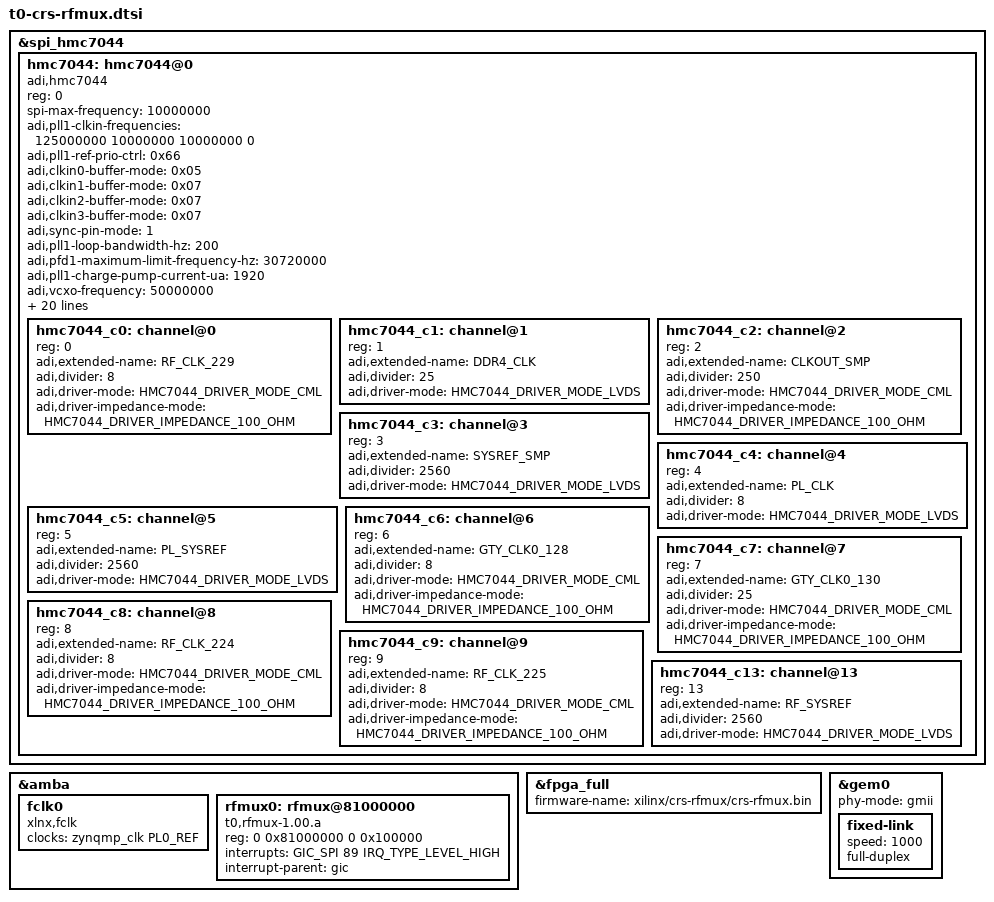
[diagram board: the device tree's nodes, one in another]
/dts-v1/;
/plugin/;

#include <dt-bindings/clock/xlnx-zynqmp-clk.h>
#include <dt-bindings/iio/frequency/hmc7044.h>
#include <dt-bindings/interrupt-controller/arm-gic.h>
#include <dt-bindings/interrupt-controller/irq.h>

&spi_hmc7044 {
	#address-cells = <1>;
	#size-cells = <0>;

	hmc7044: hmc7044@0 {
		#address-cells = <1>;
		#size-cells = <0>;
		#clock-cells = <1>;
		compatible = "adi,hmc7044";
		reg = <0>;
		spi-max-frequency = <10000000>;

		adi,pll1-clkin-frequencies = <125000000 10000000 10000000 0>;

		/* The PLL seems unable to reliably lock to the Ethernet
		* receiver clock, for $reasons we haven't had time to
		* investigate. This tends to cause poor performance. (We don't
		* control the quality of the Ethernet clock anyways, and should
		* be highly suspicious of its fine-scale performance.)
		* Removing all but the SMA and BP options until we've really
		* justified the other settings. */
		adi,pll1-ref-prio-ctrl = <0x66>; /* SMA -> BP -> SMA -> BP */

		/*adi,pll1-ref-prio-ctrl = <0x36>;*/ /* SMA -> BP -> PL -> Ethernet */

		adi,clkin0-buffer-mode  = <0x05>; /* AC */
		adi,clkin1-buffer-mode  = <0x07>; // 100Ω, AC
		adi,clkin2-buffer-mode  = <0x07>; // 100Ω, AC
		adi,clkin3-buffer-mode  = <0x07>; // 100Ω, AC
		adi,sync-pin-mode = <1>;

		adi,pll1-loop-bandwidth-hz = <200>;
		adi,pfd1-maximum-limit-frequency-hz = <30720000>;
		adi,pll1-charge-pump-current-ua = <1920>;

		adi,vcxo-frequency = <50000000>;

		adi,pll2-output-frequency = <2500000000>; /* 2.5 GHz */

		adi,sysref-timer-divider = <2560>; /* 976.5625 kHz */
		adi,pulse-generator-mode = <7>;

		adi,oscin-buffer-mode = <0x15>;

		adi,gpi-controls = <0x00 0x00 0x00 0x11>;
		adi,gpo-controls = <0x1f 0x2b 0x00 0x00>;

		adi,high-performance-mode-clock-dist-enable;

		clock-output-names =
			"hmc7044_out0_RF_CLK_229",
			"hmc7044_out1_DDR4_CLK",
			"hmc7044_out2_CLKOUT_SMP",
			"hmc7044_out3_SYSREF_SMP",
			"hmc7044_out4_PL_CLK",
			"hmc7044_out5_PL_SYSREF",
			"hmc7044_out6_GTY_CLK0_128",
			"hmc7044_out7_GTY_CLK0_130",
			"hmc7044_out8_RF_CLK_224",
			"hmc7044_out9_RF_CLK_225",
			"hmc7044_out10_RF_CLK_226",
			"hmc7044_out11_RF_CLK_227",
			"hmc7044_out12_RF_CLK_228",
			"hmc7044_out13_RF_SYSREF";

		hmc7044_c0: channel@0 {
			reg = <0>;
			adi,extended-name = "RF_CLK_229";
			adi,divider = <8>; /* 312.5 MHz */
			adi,driver-mode = <HMC7044_DRIVER_MODE_CML>;
			adi,driver-impedance-mode = <HMC7044_DRIVER_IMPEDANCE_100_OHM>;
		};
		hmc7044_c1: channel@1 {
			reg = <1>;
			adi,extended-name = "DDR4_CLK";
			adi,divider = <25>; /* 100 MHz */
			adi,driver-mode = <HMC7044_DRIVER_MODE_LVDS>;
		};
		hmc7044_c2: channel@2 {
			reg = <2>;
			adi,extended-name = "CLKOUT_SMP";
			adi,divider = <250>; /* 10 MHz */
			adi,driver-mode = <HMC7044_DRIVER_MODE_CML>;
			adi,driver-impedance-mode = <HMC7044_DRIVER_IMPEDANCE_100_OHM>;
		};
		hmc7044_c3: channel@3 {
			reg = <3>;
			adi,extended-name = "SYSREF_SMP";
			adi,divider = <2560>; /* 976.5625 kHz */
			adi,driver-mode = <HMC7044_DRIVER_MODE_LVDS>;
		};
		hmc7044_c4: channel@4 {
			reg = <4>;
			adi,extended-name = "PL_CLK";
			adi,divider = <8>; /* 312.5 MHz */
			adi,driver-mode = <HMC7044_DRIVER_MODE_LVDS>;
		};
		hmc7044_c5: channel@5 {
			reg = <5>;
			adi,extended-name = "PL_SYSREF";
			adi,divider = <2560>; /* 976.5625 kHz */
			adi,driver-mode = <HMC7044_DRIVER_MODE_LVDS>;
		};
		hmc7044_c6: channel@6 {
			reg = <6>;
			adi,extended-name = "GTY_CLK0_128";
			adi,divider = <8>; /* 312.5 MHz */
			adi,driver-mode = <HMC7044_DRIVER_MODE_CML>;
			adi,driver-impedance-mode = <HMC7044_DRIVER_IMPEDANCE_100_OHM>;
		};
		hmc7044_c7: channel@7 {
			reg = <7>;
			adi,extended-name = "GTY_CLK0_130";
			adi,divider = <25>; /* 100 MHz */
			adi,driver-mode = <HMC7044_DRIVER_MODE_CML>;
			adi,driver-impedance-mode = <HMC7044_DRIVER_IMPEDANCE_100_OHM>;
		};
		hmc7044_c8: channel@8 {
			reg = <8>;
			adi,extended-name = "RF_CLK_224";
			adi,divider = <8>; /* 312.5 MHz */
			adi,driver-mode = <HMC7044_DRIVER_MODE_CML>;
			adi,driver-impedance-mode = <HMC7044_DRIVER_IMPEDANCE_100_OHM>;
		};
		hmc7044_c9: channel@9 {
			reg = <9>;
			adi,extended-name = "RF_CLK_225";
			adi,divider = <8>; /* 312.5 MHz */
			adi,driver-mode = <HMC7044_DRIVER_MODE_CML>;
			adi,driver-impedance-mode = <HMC7044_DRIVER_IMPEDANCE_100_OHM>;
		};
#if 0
		hmc7044_c10: channel@10 {
			reg = <10>;
			adi,extended-name = "RF_CLK_226";
			adi,divider = <8>; /* 312.5 MHz */
			adi,driver-mode = <HMC7044_DRIVER_MODE_CML>;
			adi,driver-impedance-mode = <HMC7044_DRIVER_IMPEDANCE_100_OHM>;
		};
		hmc7044_c11: channel@11 {
			reg = <11>;
			adi,extended-name = "RF_CLK_227";
			adi,divider = <8>; /* 312.5 MHz */
			adi,driver-mode = <HMC7044_DRIVER_MODE_CML>;
			adi,driver-impedance-mode = <HMC7044_DRIVER_IMPEDANCE_100_OHM>;
		};
		hmc7044_c12: channel@12 {
			reg = <12>;
			adi,extended-name = "RF_CLK_228";
			adi,divider = <8>; /* 312.5 MHz */
			adi,driver-mode = <HMC7044_DRIVER_MODE_CML>;
			adi,driver-impedance-mode = <HMC7044_DRIVER_IMPEDANCE_100_OHM>;
		};
#endif
		hmc7044_c13: channel@13 {
			reg = <13>;
			adi,extended-name = "RF_SYSREF";
			adi,divider = <2560>; /* 976.5625 kHz */
			adi,driver-mode = <HMC7044_DRIVER_MODE_LVDS>;
		};
	};
};

&amba {
	/* The rfmux node overrides the SDT-generated axi_slave with a custom
	 * compatible string for the mod_rfmux kernel driver. Other PL nodes
	 * (RFDC, clocks, AFI, DDR4) are provided by the SDT via pl.dtsi.
	 *
	 * The fclk node enables pl_clk0.  The SDT/lopper flow deletes
	 * xlnx,fclk nodes from the Linux DT, so we must provide one here.
	 * Without it the PS-PL clock gate stays off and all AXI transactions
	 * to the PL hang. */

	fclk0: fclk0 {
		compatible = "xlnx,fclk";
		clocks = <&zynqmp_clk PL0_REF>;
	};

	rfmux0: rfmux@81000000 {
		#address-cells = <2>;
		#size-cells = <2>;
		reg = <0 0x81000000 0 0x100000>;
		compatible = "t0,rfmux-1.00.a";
		interrupts = <GIC_SPI 89 IRQ_TYPE_LEVEL_HIGH>; /* apparently you need to subtract 32 for reasons */
		interrupt-parent = <&gic>;
	};
};

&fpga_full {
	firmware-name = "xilinx/crs-rfmux/crs-rfmux.bin";
};

/* GEM0 drives the PL-side GMII-to-CMAC shim for 100GbE. The PHY is
 * synthetic (no MDIO), so we use fixed-link to force 1000/full. TX/RX
 * clocks are the 125 MHz fabric clock from clk_wiz; pclk/hclk come from
 * the PS as usual. */
&gem0 {
	status = "okay";
	phy-mode = "gmii";

	fixed-link {
		speed = <1000>;
		full-duplex;
	};
};
